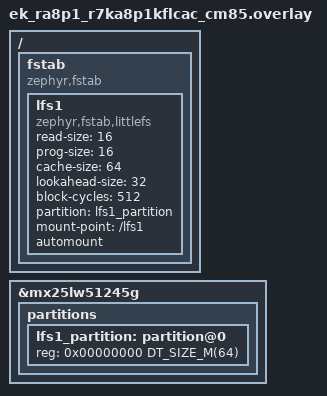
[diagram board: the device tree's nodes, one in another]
/*
 * Copyright (c) 2026 Renesas Electronics Corporation
 *
 * SPDX-License-Identifier: Apache-2.0
 */

&mx25lw51245g {
	partitions {
		/delete-node/ partition;

		/* 64MiB external storage partition */
		lfs1_partition: partition@0 {
			reg = <0x00000000 DT_SIZE_M(64)>;
		};
	};
};

/ {
	fstab {
		compatible = "zephyr,fstab";
		lfs1: lfs1 {
			compatible = "zephyr,fstab,littlefs";
			read-size = <16>;
			prog-size = <16>;
			cache-size = <64>;
			lookahead-size = <32>;
			block-cycles = <512>;
			partition = <&lfs1_partition>;
			mount-point = "/lfs1";
			automount;
		};
	};
};

